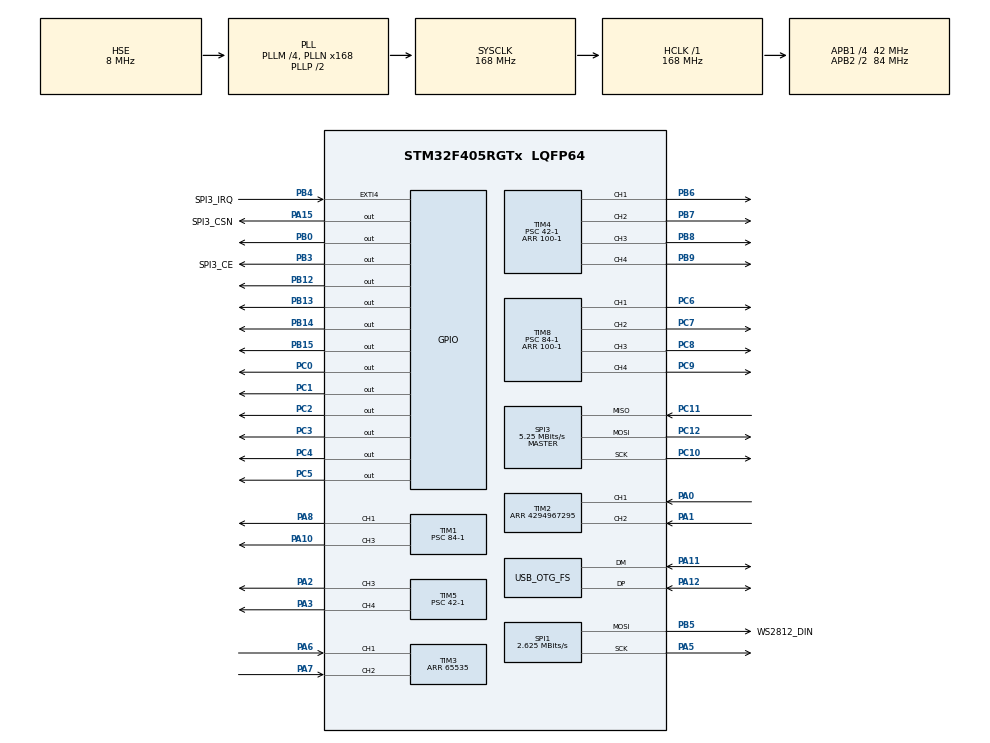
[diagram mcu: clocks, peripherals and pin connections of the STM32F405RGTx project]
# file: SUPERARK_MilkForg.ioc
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Dma.Request0=SPI1_TX
Dma.SPI1_TX.0.Direction=DMA_MEMORY_TO_PERIPH
Dma.SPI1_TX.0.FIFOMode=DMA_FIFOMODE_DISABLE
Dma.SPI1_TX.0.Instance=DMA2_Stream3
Dma.SPI1_TX.0.MemDataAlignment=DMA_MDATAALIGN_BYTE
Dma.SPI1_TX.0.MemInc=DMA_MINC_ENABLE
Dma.SPI1_TX.0.Mode=DMA_NORMAL
Dma.SPI1_TX.0.PeriphDataAlignment=DMA_PDATAALIGN_BYTE
Dma.SPI1_TX.0.PeriphInc=DMA_PINC_DISABLE
Dma.SPI1_TX.0.Priority=DMA_PRIORITY_VERY_HIGH
FREERTOS.Tasks01=defaultTask,24,256,StartDefaultTask,Default,NULL,Dynamic,NULL,NULL;remoteTask,24,512,StartRemoteTask,As weak,NULL,Dynamic,NULL,NULL;ws2812Task,8,512,StartWs2812Task,As weak,NULL,Dynamic,NULL,NULL;chassisTask,40,512,StartChassicTask,As weak,NULL,Dynamic,NULL,NULL
FREERTOS.configTOTAL_HEAP_SIZE=15360
Mcu.Family=STM32F4
Mcu.Name=STM32F405RGTx
Mcu.Package=LQFP64
NVIC.DMA2_Stream3_IRQn=true\:5\:0\:false\:false\:true\:true\:false\:true\:true
NVIC.EXTI4_IRQn=true\:5\:0\:false\:false\:true\:true\:true\:true\:true
NVIC.OTG_FS_IRQn=true\:5\:0\:false\:false\:true\:true\:false\:true\:true
NVIC.PriorityGroup=NVIC_PRIORITYGROUP_4
NVIC.SPI1_IRQn=true\:5\:0\:false\:false\:true\:true\:false\:true\:true
NVIC.TIM6_DAC_IRQn=true\:15\:0\:false\:false\:true\:false\:false\:true\:true
NVIC.TimeBase=TIM6_DAC_IRQn
NVIC.TimeBaseIP=TIM6
PA0-WKUP.GPIO_Speed=GPIO_SPEED_FREQ_HIGH
PA0-WKUP.Signal=S_TIM2_CH1_ETR
PA1.GPIO_Speed=GPIO_SPEED_FREQ_HIGH
PA1.Signal=S_TIM2_CH2
PA10.GPIO_Speed=GPIO_SPEED_FREQ_HIGH
PA10.Signal=S_TIM1_CH3
PA11.Mode=Device_Only
PA11.Signal=USB_OTG_FS_DM
PA12.Mode=Device_Only
PA12.Signal=USB_OTG_FS_DP
PA13.Mode=Serial_Wire
PA13.Signal=SYS_JTMS-SWDIO
PA14.Mode=Serial_Wire
PA14.Signal=SYS_JTCK-SWCLK
PA15.GPIO_Label=SPI3_CSN
PA15.Signal=GPIO_Output
PA2.GPIO_Speed=GPIO_SPEED_FREQ_HIGH
PA2.Signal=S_TIM5_CH3
PA3.GPIO_Speed=GPIO_SPEED_FREQ_HIGH
PA3.Signal=S_TIM5_CH4
PA5.Mode=TX_Only_Simplex_Unidirect_Master
PA5.Signal=SPI1_SCK
PA6.GPIO_Speed=GPIO_SPEED_FREQ_HIGH
PA6.Signal=S_TIM3_CH1
PA7.GPIO_Speed=GPIO_SPEED_FREQ_HIGH
PA7.Signal=S_TIM3_CH2
PA8.GPIO_Speed=GPIO_SPEED_FREQ_HIGH
PA8.Signal=S_TIM1_CH1
PB0.Signal=GPIO_Output
PB12.Signal=GPIO_Output
PB13.Signal=GPIO_Output
PB14.Signal=GPIO_Output
PB15.Signal=GPIO_Output
PB3.GPIO_Label=SPI3_CE
PB3.Signal=GPIO_Output
PB4.GPIO_Label=SPI3_IRQ
PB4.GPIO_ModeDefaultEXTI=GPIO_MODE_IT_FALLING
PB4.GPIO_PuPd=GPIO_PULLUP
PB4.Signal=GPXTI4
PB5.GPIO_Label=WS2812_DIN
PB5.Mode=TX_Only_Simplex_Unidirect_Master
PB5.Signal=SPI1_MOSI
PB6.GPIO_Speed=GPIO_SPEED_FREQ_HIGH
PB6.Signal=S_TIM4_CH1
PB7.GPIO_Speed=GPIO_SPEED_FREQ_HIGH
PB7.Signal=S_TIM4_CH2
PB8.GPIO_Speed=GPIO_SPEED_FREQ_HIGH
PB8.Signal=S_TIM4_CH3
PB9.GPIO_Speed=GPIO_SPEED_FREQ_HIGH
PB9.Signal=S_TIM4_CH4
PC0.Signal=GPIO_Output
PC1.Signal=GPIO_Output
PC10.Mode=Full_Duplex_Master
PC10.Signal=SPI3_SCK
PC11.Mode=Full_Duplex_Master
PC11.Signal=SPI3_MISO
PC12.Mode=Full_Duplex_Master
PC12.Signal=SPI3_MOSI
PC2.Signal=GPIO_Output
PC3.Signal=GPIO_Output
PC4.Signal=GPIO_Output
PC5.Signal=GPIO_Output
PC6.GPIO_Speed=GPIO_SPEED_FREQ_HIGH
PC6.Signal=S_TIM8_CH1
PC7.GPIO_Speed=GPIO_SPEED_FREQ_HIGH
PC7.Signal=S_TIM8_CH2
PC8.GPIO_Speed=GPIO_SPEED_FREQ_HIGH
PC8.Signal=S_TIM8_CH3
PC9.GPIO_Speed=GPIO_SPEED_FREQ_HIGH
PC9.Signal=S_TIM8_CH4
PH0-OSC_IN.Mode=HSE-External-Oscillator
PH0-OSC_IN.Signal=RCC_OSC_IN
PH1-OSC_OUT.Mode=HSE-External-Oscillator
PH1-OSC_OUT.Signal=RCC_OSC_OUT
ProjectManager.HeapSize=0x200
ProjectManager.StackSize=0x400
ProjectManager.TargetToolchain=CMake
RCC.48MHZClocksFreq_Value=48000000
RCC.AHBFreq_Value=168000000
RCC.APB1CLKDivider=RCC_HCLK_DIV4
RCC.APB1Freq_Value=42000000
RCC.APB1TimFreq_Value=84000000
RCC.APB2CLKDivider=RCC_HCLK_DIV2
RCC.APB2Freq_Value=84000000
RCC.APB2TimFreq_Value=168000000
RCC.CortexFreq_Value=168000000
RCC.HCLKFreq_Value=168000000
RCC.HSE_VALUE=8000000
RCC.HSI_VALUE=16000000
RCC.LSE_VALUE=32768
RCC.PLLM=4
RCC.PLLN=168
RCC.PLLQ=7
RCC.SYSCLKFreq_VALUE=168000000
RCC.SYSCLKSource=RCC_SYSCLKSOURCE_PLLCLK
RCC.VCOOutputFreq_Value=336000000
SH.S_TIM1_CH1.0=TIM1_CH1,PWM Generation1 CH1
SH.S_TIM1_CH3.0=TIM1_CH3,PWM Generation3 CH3
SH.S_TIM2_CH1_ETR.0=TIM2_CH1,Encoder_Interface
SH.S_TIM2_CH2.0=TIM2_CH2,Encoder_Interface
SH.S_TIM3_CH1.0=TIM3_CH1,Encoder_Interface
SH.S_TIM3_CH2.0=TIM3_CH2,Encoder_Interface
SH.S_TIM4_CH1.0=TIM4_CH1,PWM Generation1 CH1
SH.S_TIM4_CH2.0=TIM4_CH2,PWM Generation2 CH2
SH.S_TIM4_CH3.0=TIM4_CH3,PWM Generation3 CH3
SH.S_TIM4_CH4.0=TIM4_CH4,PWM Generation4 CH4
SH.S_TIM5_CH3.0=TIM5_CH3,PWM Generation3 CH3
SH.S_TIM5_CH4.0=TIM5_CH4,PWM Generation4 CH4
SH.S_TIM8_CH1.0=TIM8_CH1,PWM Generation1 CH1
SH.S_TIM8_CH2.0=TIM8_CH2,PWM Generation2 CH2
SH.S_TIM8_CH3.0=TIM8_CH3,PWM Generation3 CH3
SH.S_TIM8_CH4.0=TIM8_CH4,PWM Generation4 CH4
SPI1.BaudRatePrescaler=SPI_BAUDRATEPRESCALER_32
SPI1.CalculateBaudRate=2.625 MBits/s
SPI1.Direction=SPI_DIRECTION_2LINES
SPI1.Mode=SPI_MODE_MASTER
SPI1.VirtualType=VM_MASTER
SPI3.BaudRatePrescaler=SPI_BAUDRATEPRESCALER_8
SPI3.CalculateBaudRate=5.25 MBits/s
SPI3.Direction=SPI_DIRECTION_2LINES
SPI3.Mode=SPI_MODE_MASTER
SPI3.VirtualType=VM_MASTER
TIM1.AutoReloadPreload=TIM_AUTORELOAD_PRELOAD_ENABLE
TIM1.Channel-PWM\ Generation1\ CH1=TIM_CHANNEL_1
TIM1.Channel-PWM\ Generation3\ CH3=TIM_CHANNEL_3
TIM1.Period=100-1
TIM1.Prescaler=84-1
TIM2.AutoReloadPreload=TIM_AUTORELOAD_PRELOAD_ENABLE
TIM2.EncoderMode=TIM_ENCODERMODE_TI12
TIM2.IC1Filter=6
TIM2.IC2Filter=6
TIM2.Period=4294967295
TIM3.AutoReloadPreload=TIM_AUTORELOAD_PRELOAD_ENABLE
TIM3.EncoderMode=TIM_ENCODERMODE_TI12
TIM3.IC1Filter=6
TIM3.IC2Filter=6
TIM3.Period=65535
TIM4.AutoReloadPreload=TIM_AUTORELOAD_PRELOAD_ENABLE
TIM4.Channel-PWM\ Generation1\ CH1=TIM_CHANNEL_1
TIM4.Channel-PWM\ Generation2\ CH2=TIM_CHANNEL_2
TIM4.Channel-PWM\ Generation3\ CH3=TIM_CHANNEL_3
TIM4.Channel-PWM\ Generation4\ CH4=TIM_CHANNEL_4
TIM4.Period=100-1
TIM4.Prescaler=42-1
TIM5.AutoReloadPreload=TIM_AUTORELOAD_PRELOAD_ENABLE
TIM5.Channel-PWM\ Generation3\ CH3=TIM_CHANNEL_3
TIM5.Channel-PWM\ Generation4\ CH4=TIM_CHANNEL_4
TIM5.Period=100-1
TIM5.Prescaler=42-1
TIM8.AutoReloadPreload=TIM_AUTORELOAD_PRELOAD_ENABLE
TIM8.Channel-PWM\ Generation1\ CH1=TIM_CHANNEL_1
TIM8.Channel-PWM\ Generation2\ CH2=TIM_CHANNEL_2
TIM8.Channel-PWM\ Generation3\ CH3=TIM_CHANNEL_3
TIM8.Channel-PWM\ Generation4\ CH4=TIM_CHANNEL_4
TIM8.Period=100-1
TIM8.Prescaler=84-1
USB_DEVICE.CLASS_NAME_FS=CDC
USB_DEVICE.VirtualMode-CDC_FS=Cdc
USB_DEVICE.VirtualModeFS=Cdc_FS
USB_OTG_FS.VirtualMode=Device_Only
VP_FREERTOS_VS_CMSIS_V2.Mode=CMSIS_V2
VP_SYS_VS_tim6.Mode=TIM6
VP_TIM4_VS_ClockSourceINT.Mode=Internal
VP_TIM8_VS_ClockSourceINT.Mode=Internal
VP_USB_DEVICE_VS_USB_DEVICE_CDC_FS.Mode=CDC_FS
board=custom

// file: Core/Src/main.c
/* USER CODE BEGIN Header */
/**
  ******************************************************************************
  * @file           : main.c
  * @brief          : Main program body
  ******************************************************************************
  * @attention
  *
  * Copyright (c) 2026 STMicroelectronics.
  * All rights reserved.
  *
  * This software is licensed under terms that can be found in the LICENSE file
  * in the root directory of this software component.
  * If no LICENSE file comes with this software, it is provided AS-IS.
  *
  ******************************************************************************
  */
/* USER CODE END Header */
#include "main.h"
#include "cmsis_os.h"
#include "dma.h"
#include "spi.h"
#include "tim.h"
#include "usb_device.h"
#include "gpio.h"

/* USER CODE BEGIN Includes */
#include "bsp_dwt.h"
#include "bsp_encoder.h"
#include "bsp_pwm.h"

/* USER CODE END Includes */

/* USER CODE BEGIN PD */
#define IR2104_MOTOR_TEST_ENABLE 0U
#define IR2104_MOTOR_TEST_DUTY 10U
#define IR2104_DEADTIME_US 10U

/* USER CODE END PD */

void SystemClock_Config(void);
void MX_FREERTOS_Init(void);

int main(void)
{

  /* MCU Configuration--------------------------------------------------------*/

  /* Reset of all peripherals, Initializes the Flash interface and the Systick. */
  HAL_Init();

  /* Configure the system clock */
  SystemClock_Config();

  /* Initialize all configured peripherals */
  MX_GPIO_Init();
  MX_DMA_Init();
  MX_SPI1_Init();
  MX_SPI3_Init();
  MX_TIM4_Init();
  MX_TIM8_Init();
  MX_TIM1_Init();
  MX_TIM2_Init();
  MX_TIM3_Init();
  MX_TIM5_Init();
  /* USER CODE BEGIN 2 */
  Bsp_Encoder_Init();
  Bsp_Pwm_Init();

  /* USER CODE END 2 */

  /* Init scheduler */
  osKernelInitialize();  /* Call init function for freertos objects (in cmsis_os2.c) */
  MX_FREERTOS_Init();

  /* Start scheduler */
  osKernelStart();

  /* We should never get here as control is now taken by the scheduler */

  /* Infinite loop */
  while (1)
  {

  }
}

void SystemClock_Config(void)
{
  RCC_OscInitTypeDef RCC_OscInitStruct = {0};
  RCC_ClkInitTypeDef RCC_ClkInitStruct = {0};

  /** Configure the main internal regulator output voltage
  */
  __HAL_RCC_PWR_CLK_ENABLE();
  __HAL_PWR_VOLTAGESCALING_CONFIG(PWR_REGULATOR_VOLTAGE_SCALE1);

  /** Initializes the RCC Oscillators according to the specified parameters
  * in the RCC_OscInitTypeDef structure.
  */
  RCC_OscInitStruct.OscillatorType = RCC_OSCILLATORTYPE_HSE;
  RCC_OscInitStruct.HSEState = RCC_HSE_ON;
  RCC_OscInitStruct.PLL.PLLState = RCC_PLL_ON;
  RCC_OscInitStruct.PLL.PLLSource = RCC_PLLSOURCE_HSE;
  RCC_OscInitStruct.PLL.PLLM = 4;
  RCC_OscInitStruct.PLL.PLLN = 168;
  RCC_OscInitStruct.PLL.PLLP = RCC_PLLP_DIV2;
  RCC_OscInitStruct.PLL.PLLQ = 7;
  if (HAL_RCC_OscConfig(&RCC_OscInitStruct) != HAL_OK)
  {
    Error_Handler();
  }

  /** Initializes the CPU, AHB and APB buses clocks
  */
  RCC_ClkInitStruct.ClockType = RCC_CLOCKTYPE_HCLK|RCC_CLOCKTYPE_SYSCLK
                              |RCC_CLOCKTYPE_PCLK1|RCC_CLOCKTYPE_PCLK2;
  RCC_ClkInitStruct.SYSCLKSource = RCC_SYSCLKSOURCE_PLLCLK;
  RCC_ClkInitStruct.AHBCLKDivider = RCC_SYSCLK_DIV1;
  RCC_ClkInitStruct.APB1CLKDivider = RCC_HCLK_DIV4;
  RCC_ClkInitStruct.APB2CLKDivider = RCC_HCLK_DIV2;

  if (HAL_RCC_ClockConfig(&RCC_ClkInitStruct, FLASH_LATENCY_5) != HAL_OK)
  {
    Error_Handler();
  }
}

void HAL_TIM_PeriodElapsedCallback(TIM_HandleTypeDef *htim)
{
  if (htim->Instance == TIM6)
  {
    HAL_IncTick();
  }
}

void Error_Handler(void)
{
  __disable_irq();
  while (1)
  {
  }
}

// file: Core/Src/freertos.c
/* USER CODE BEGIN Header */
/**
  ******************************************************************************
  * File Name          : freertos.c
  * Description        : Code for freertos applications
  ******************************************************************************
  * @attention
  *
  * Copyright (c) 2026 STMicroelectronics.
  * All rights reserved.
  *
  * This software is licensed under terms that can be found in the LICENSE file
  * in the root directory of this software component.
  * If no LICENSE file comes with this software, it is provided AS-IS.
  *
  ******************************************************************************
  */
/* USER CODE END Header */

#include "FreeRTOS.h"
#include "task.h"
#include "main.h"
#include "cmsis_os.h"

/* USER CODE BEGIN Includes */
#include "app_remote_task.h"
#include "app_ws2812_task.h"

/* USER CODE END Includes */

/* Definitions for defaultTask */
osThreadId_t defaultTaskHandle;
const osThreadAttr_t defaultTask_attributes = {
  .name = "defaultTask",
  .stack_size = 256 * 4,
  .priority = (osPriority_t) osPriorityNormal,
};
/* Definitions for remoteTask */
osThreadId_t remoteTaskHandle;
const osThreadAttr_t remoteTask_attributes = {
  .name = "remoteTask",
  .stack_size = 512 * 4,
  .priority = (osPriority_t) osPriorityNormal,
};
/* Definitions for ws2812Task */
osThreadId_t ws2812TaskHandle;
const osThreadAttr_t ws2812Task_attributes = {
  .name = "ws2812Task",
  .stack_size = 512 * 4,
  .priority = (osPriority_t) osPriorityLow,
};
/* Definitions for chassisTask */
osThreadId_t chassisTaskHandle;
const osThreadAttr_t chassisTask_attributes = {
  .name = "chassisTask",
  .stack_size = 512 * 4,
  .priority = (osPriority_t) osPriorityHigh,
};

void StartDefaultTask(void *argument);
void StartRemoteTask(void *argument);
void StartWs2812Task(void *argument);
void StartChassicTask(void *argument);

extern void MX_USB_DEVICE_Init(void);
void MX_FREERTOS_Init(void); /* (MISRA C 2004 rule 8.1) */

void MX_FREERTOS_Init(void) {

  /* Create the thread(s) */
  /* creation of defaultTask */
  defaultTaskHandle = osThreadNew(StartDefaultTask, NULL, &defaultTask_attributes);

  /* creation of remoteTask */
  remoteTaskHandle = osThreadNew(StartRemoteTask, NULL, &remoteTask_attributes);

  /* creation of ws2812Task */
  ws2812TaskHandle = osThreadNew(StartWs2812Task, NULL, &ws2812Task_attributes);

  /* creation of chassisTask */
  chassisTaskHandle = osThreadNew(StartChassicTask, NULL, &chassisTask_attributes);

}

void StartDefaultTask(void *argument)
{
  /* init code for USB_DEVICE */
  MX_USB_DEVICE_Init();
  /* USER CODE BEGIN StartDefaultTask */

  /* Infinite loop */
  for(;;)
  {
    osDelay(1000);
  }
  /* USER CODE END StartDefaultTask */
}

__weak void StartRemoteTask(void *argument)
{
  for(;;)
  {
    osDelay(1);
  }
}

__weak void StartWs2812Task(void *argument)
{
  for(;;)
  {
    osDelay(1);
  }
}

__weak void StartChassicTask(void *argument)
{
  for(;;)
  {
    osDelay(1);
  }
}
